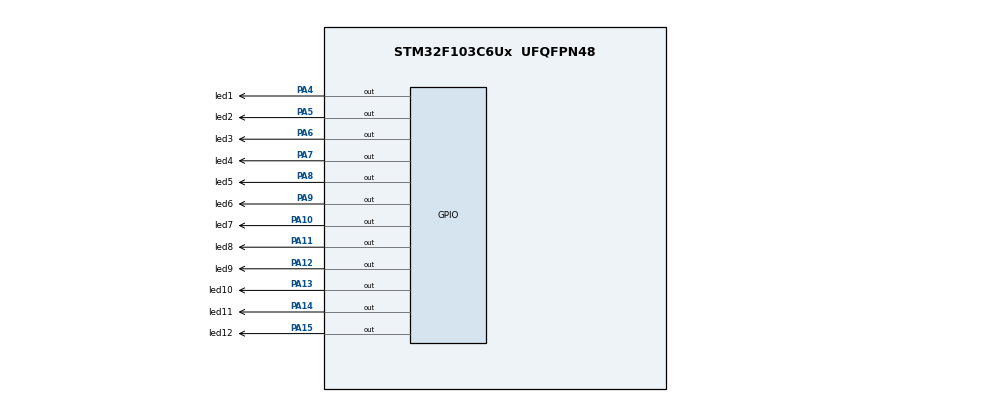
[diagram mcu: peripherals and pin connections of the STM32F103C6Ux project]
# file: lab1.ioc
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Mcu.Family=STM32F1
Mcu.Name=STM32F103C6Ux
Mcu.Package=UFQFPN48
NVIC.PriorityGroup=NVIC_PRIORITYGROUP_4
PA10.GPIO_Label=led7
PA10.Signal=GPIO_Output
PA11.GPIO_Label=led8
PA11.Signal=GPIO_Output
PA12.GPIO_Label=led9
PA12.Signal=GPIO_Output
PA13.GPIO_Label=led10
PA13.Signal=GPIO_Output
PA14.GPIO_Label=led11
PA14.Signal=GPIO_Output
PA15.GPIO_Label=led12
PA15.Signal=GPIO_Output
PA4.GPIO_Label=led1
PA4.Signal=GPIO_Output
PA5.GPIO_Label=led2
PA5.Signal=GPIO_Output
PA6.GPIO_Label=led3
PA6.Signal=GPIO_Output
PA7.GPIO_Label=led4
PA7.Signal=GPIO_Output
PA8.GPIO_Label=led5
PA8.Signal=GPIO_Output
PA9.GPIO_Label=led6
PA9.Signal=GPIO_Output
ProjectManager.HeapSize=0x200
ProjectManager.StackSize=0x400
ProjectManager.TargetToolchain=STM32CubeIDE
RCC.APB1Freq_Value=8000000
RCC.APB2Freq_Value=8000000
board=custom

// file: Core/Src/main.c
/* USER CODE BEGIN Header */
/**
  ******************************************************************************
  * @file           : main.c
  * @brief          : Main program body
  ******************************************************************************
  * @attention
  *
  * Copyright (c) 2023 STMicroelectronics.
  * All rights reserved.
  *
  * This software is licensed under terms that can be found in the LICENSE file
  * in the root directory of this software component.
  * If no LICENSE file comes with this software, it is provided AS-IS.
  *
  ******************************************************************************
  */
/* USER CODE END Header */
#include "main.h"

/* USER CODE BEGIN PD */
uint16_t segmentPin[12] = {led1_Pin, led2_Pin, led3_Pin, led4_Pin, led5_Pin, led6_Pin, led7_Pin,
							led8_Pin, led9_Pin, led10_Pin, led11_Pin, led12_Pin};
GPIO_TypeDef* segmentPort[12] = {led1_GPIO_Port, led2_GPIO_Port, led3_GPIO_Port, led4_GPIO_Port, led5_GPIO_Port, led6_GPIO_Port, led7_GPIO_Port,
		led8_GPIO_Port, led9_GPIO_Port, led10_GPIO_Port, led11_GPIO_Port, led12_GPIO_Port};
/* USER CODE END PD */

void SystemClock_Config(void);
static void MX_GPIO_Init(void);
void clearAllClock () {
	for (int i = 0; i < 12; i++) {
		HAL_GPIO_WritePin(segmentPort[i], segmentPin[i], GPIO_PIN_SET);
	}
}
void setNumberOnClock(int num) {
	HAL_GPIO_WritePin(segmentPort[num], segmentPin[num], GPIO_PIN_RESET);
}
void clearNumberOnClock(int num) {
	HAL_GPIO_WritePin(segmentPort[num], segmentPin[num], GPIO_PIN_SET);
}

int main(void)
{

  /* MCU Configuration--------------------------------------------------------*/

  /* Reset of all peripherals, Initializes the Flash interface and the Systick. */
  HAL_Init();

  /* Configure the system clock */
  SystemClock_Config();

  /* Initialize all configured peripherals */
  MX_GPIO_Init();
int sec = 0;
int min = 0;
int hour = 0;

  /* Infinite loop */
  while (1)
  {
	 if (sec == 0 && min == 0 && hour == 0) {
		 clearAllClock();
	 }
	 if (sec%5 == 0) {
		 if (sec - 5 >= 0) {
			 clearNumberOnClock((sec-5)/5);
		 }

	 }
	 if (sec >= 60)  {
		 sec = 0;
		 min++;
		 if (min%5 == 0) {
			 if (min - 5 >= 0) {
				 clearNumberOnClock((min-5)/5);
			 }

		 }
		 if (min >= 60) {
			 min = 0;
			 hour++;
			 if (hour - 1>= 0)
			 clearNumberOnClock(hour-1);
			 if (hour >= 12 ) {
				 hour = 0;
			 }
		 }
	 }
	 setNumberOnClock(sec/5);
	 	 setNumberOnClock(min/5);
	 	 setNumberOnClock(hour);
	sec++;
	HAL_Delay(1000);

  }
}

void SystemClock_Config(void)
{
  RCC_OscInitTypeDef RCC_OscInitStruct = {0};
  RCC_ClkInitTypeDef RCC_ClkInitStruct = {0};

  /** Initializes the RCC Oscillators according to the specified parameters
  * in the RCC_OscInitTypeDef structure.
  */
  RCC_OscInitStruct.OscillatorType = RCC_OSCILLATORTYPE_HSI;
  RCC_OscInitStruct.HSIState = RCC_HSI_ON;
  RCC_OscInitStruct.HSICalibrationValue = RCC_HSICALIBRATION_DEFAULT;
  RCC_OscInitStruct.PLL.PLLState = RCC_PLL_NONE;
  if (HAL_RCC_OscConfig(&RCC_OscInitStruct) != HAL_OK)
  {
    Error_Handler();
  }

  /** Initializes the CPU, AHB and APB buses clocks
  */
  RCC_ClkInitStruct.ClockType = RCC_CLOCKTYPE_HCLK|RCC_CLOCKTYPE_SYSCLK
                              |RCC_CLOCKTYPE_PCLK1|RCC_CLOCKTYPE_PCLK2;
  RCC_ClkInitStruct.SYSCLKSource = RCC_SYSCLKSOURCE_HSI;
  RCC_ClkInitStruct.AHBCLKDivider = RCC_SYSCLK_DIV1;
  RCC_ClkInitStruct.APB1CLKDivider = RCC_HCLK_DIV1;
  RCC_ClkInitStruct.APB2CLKDivider = RCC_HCLK_DIV1;

  if (HAL_RCC_ClockConfig(&RCC_ClkInitStruct, FLASH_LATENCY_0) != HAL_OK)
  {
    Error_Handler();
  }
}

static void MX_GPIO_Init(void)
{
  GPIO_InitTypeDef GPIO_InitStruct = {0};

  /* GPIO Ports Clock Enable */
  __HAL_RCC_GPIOA_CLK_ENABLE();

  /*Configure GPIO pin Output Level */
  HAL_GPIO_WritePin(GPIOA, led1_Pin|led2_Pin|led3_Pin|led4_Pin
                          |led5_Pin|led6_Pin|led7_Pin|led8_Pin
                          |led9_Pin|led10_Pin|led11_Pin|led12_Pin, GPIO_PIN_RESET);

  /*Configure GPIO pins : led1_Pin led2_Pin led3_Pin led4_Pin
                           led5_Pin led6_Pin led7_Pin led8_Pin
                           led9_Pin led10_Pin led11_Pin led12_Pin */
  GPIO_InitStruct.Pin = led1_Pin|led2_Pin|led3_Pin|led4_Pin
                          |led5_Pin|led6_Pin|led7_Pin|led8_Pin
                          |led9_Pin|led10_Pin|led11_Pin|led12_Pin;
  GPIO_InitStruct.Mode = GPIO_MODE_OUTPUT_PP;
  GPIO_InitStruct.Pull = GPIO_NOPULL;
  GPIO_InitStruct.Speed = GPIO_SPEED_FREQ_LOW;
  HAL_GPIO_Init(GPIOA, &GPIO_InitStruct);

}

void Error_Handler(void)
{
  __disable_irq();
  while (1)
  {
  }
}
